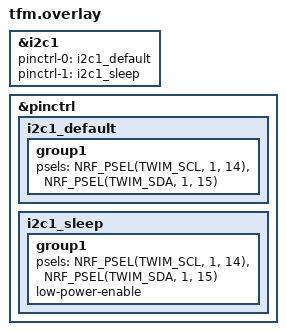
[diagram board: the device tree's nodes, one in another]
/* SPDX-License-Identifier: Apache-2.0 */

/*
 * TWIM1 (i2c1) is Secure-only by default. Declaring it here so the TF-M
 * (secure) image's own devicetree also sees it enabled, which is what makes
 * TF-M assign it Non-Secure ownership in the SPU config. Without this, the
 * non-secure app faults (SecureFault escalated to HardFault) the moment
 * nrfx_twim_init() writes to TWIM1's registers.
 */

&i2c1 {
	status = "okay";
	pinctrl-0 = <&i2c1_default>;
	pinctrl-1 = <&i2c1_sleep>;
	pinctrl-names = "default", "sleep";
};

&pinctrl {
	/omit-if-no-ref/ i2c1_default: i2c1_default {
		group1 {
			psels = <NRF_PSEL(TWIM_SCL, 1, 14)>,
				<NRF_PSEL(TWIM_SDA, 1, 15)>;
		};
	};

	/omit-if-no-ref/ i2c1_sleep: i2c1_sleep {
		group1 {
			psels = <NRF_PSEL(TWIM_SCL, 1, 14)>,
				<NRF_PSEL(TWIM_SDA, 1, 15)>;
			low-power-enable;
		};
	};
};
